# LPC54S018M register map
Vendor: nxp.com; File version: 1.0
CPU: CM4 r0p1, little endian, MPU, FPU, VTOR, 3 interrupt priority bits
Registers are 32-bit, read-write, reset 0x0 unless marked. A register's access mark holds for its fields unless they carry their own. Offsets are from the block's base; [hi:lo] are bit positions; {n}, {i} and the like mark numbered series; 'fields as' and 'values as' point back to an identical list.

## CRC_ENGINE — LPC5411x CRC engine
Base 0x40095000
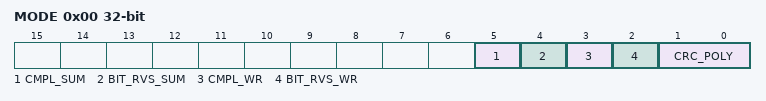
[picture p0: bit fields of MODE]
0x00 MODE — CRC mode register
  [5] CMPL_SUM — CRC sum complement: 1 = 1's complement for CRC_SUM 0 = No 1's complement for CRC_SUM
  [4] BIT_RVS_SUM — CRC sum bit order: 1 = Bit order reverse for CRC_SUM 0 = No bit order reverse for CRC_SUM
  [3] CMPL_WR — Data complement: 1 = 1's complement for CRC_WR_DATA 0 = No 1's complement for CRC_WR_DATA
  [2] BIT_RVS_WR — Data bit order: 1 = Bit order reverse for CRC_WR_DATA (per byte) 0 = No bit order reverse for CRC_WR_DATA (per byte)
  [1:0] CRC_POLY — CRC polynomial: 1X = CRC-32 polynomial 01 = CRC-16 polynomial 00 = CRC-CCITT polynomial
0x04 SEED reset 0xFFFF — CRC seed register
  [31:0] CRC_SEED — A write access to this register will load CRC seed value to CRC_SUM register with selected bit order and 1's complement pre-processes. A write access to this register will overrule the CRC calculation in progresses.
0x08 SUM ro reset 0xFFFF (SUM_WR_DATA view) — CRC checksum register
  [31:0] CRC_SUM — The most recent CRC sum can be read through this register with selected bit order and 1's complement post-processes.
0x08 WR_DATA wo (SUM_WR_DATA view) — CRC data register
  [31:0] CRC_WR_DATA — Data written to this register will be taken to perform CRC calculation with selected bit order and 1's complement pre-process. Any write size 8, 16 or 32-bit are allowed and accept back-to-back transactions.

## AES0 — AES
Base 0x400A1000
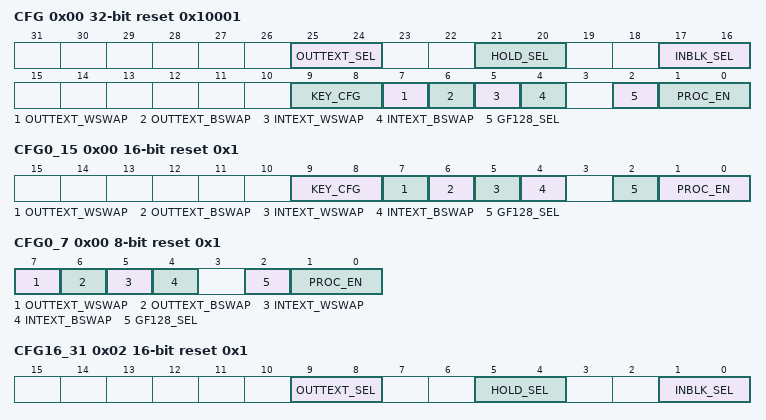
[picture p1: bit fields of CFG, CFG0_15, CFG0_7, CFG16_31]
0x00 CFG reset 0x10001 (CFG_CFG0_15_CFG0_7 view) — AES Configuration register
  [25:24] OUTTEXT_SEL — Output text source select.
  [21:20] HOLD_SEL — Holding register source select.
  [17:16] INBLK_SEL — Input block select.
  [9:8] KEY_CFG — Key Configuration.
  [7] OUTTEXT_WSWAP — Word swap output text.
  [6] OUTTEXT_BSWAP — Byte swap output text.
  [5] INTEXT_WSWAP — Word swap input text.
  [4] INTEXT_BSWAP — Byte swap input text.
  [2] GF128_SEL — GF128 hash selection.
  [1:0] PROC_EN — Process type enable.
0x00 CFG0_15 16-bit reset 0x1 (CFG_CFG0_15_CFG0_7 view) — AES Configuration register 0:15
  [9:8] KEY_CFG — Key Configuration.
  [7] OUTTEXT_WSWAP — Word swap output text.
  [6] OUTTEXT_BSWAP — Byte swap output text.
  [5] INTEXT_WSWAP — Word swap input text.
  [4] INTEXT_BSWAP — Byte swap input text.
  [2] GF128_SEL — GF128 hash selection.
  [1:0] PROC_EN — Process type enable.
0x00 CFG0_7 8-bit reset 0x1 (CFG_CFG0_15_CFG0_7 view) — AES Configuration register 0:7
  [7] OUTTEXT_WSWAP — Word swap output text.
  [6] OUTTEXT_BSWAP — Byte swap output text.
  [5] INTEXT_WSWAP — Word swap input text.
  [4] INTEXT_BSWAP — Byte swap input text.
  [2] GF128_SEL — GF128 hash selection.
  [1:0] PROC_EN — Process type enable.
0x01 CFG8_15 8-bit — AES Configuration register 8:15
  [1:0] KEY_CFG — Key Configuration.
0x02 CFG16_31 16-bit reset 0x1 — AES Configuration register 16:31
  [9:8] OUTTEXT_SEL — Output text source select.
  [5:4] HOLD_SEL — Holding register source select.
  [1:0] INBLK_SEL — Input block select.
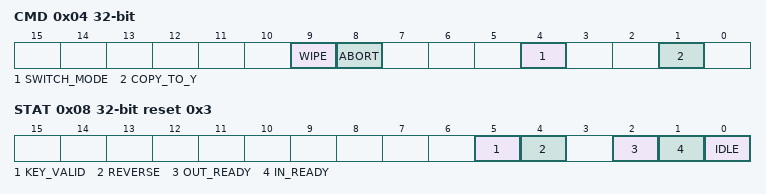
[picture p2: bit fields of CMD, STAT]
0x04 CMD — AES Command register
  [9] WIPE — When set this bit performs abort, clears KEY and GF128_Y registers and disables cipher.
  [8] ABORT — Aborts Encrypt/Decrypt and GF128 Hash operation.
  [4] SWITCH_MODE — When this bit is set the mode switches from forward mode (encryption) to reverse mode (decryption) or reverse mode to forward mode.
  [1] COPY_TO_Y — Copy output text to GF128Y.
0x08 STAT reset 0x3 — AES Status register
  [5] KEY_VALID
  [4] REVERSE — Reverse mode.
  [2] OUT_READY — Output text ready.
  [1] IN_READY — Input text ready.
  [0] IDLE — AES engine Idle.
0x0C CTR_INCR — Counter Increment
  [31:0] CTR_INCR — Increment value for HOLDING register when in counter modes.
{0x20+4i} KEY[{i}] (i=0..7) wo — Bits of the AES key
  [31:0] KEY — Contains the bits of the AES key.
{0x40+4i} INTEXT[{i}] (i=0..3) wo — Input text bits
  [31:0] INTEXT — Contains bits of the AES key.
{0x50+4i} HOLDING[{i}] (i=0..3) wo — Holding register bits
  [31:0] HOLDING — Contains the first word (bits 31:0) of the 128 bit Holding value.
{0x60+4i} OUTTEXT[{i}] (i=0..3) ro — Output text bits
  [31:0] OUTTEXT — Contains the bits of the 128 bit Output text data.
{0x70+4i} GF128_Y[{i}] (i=0..3) wo — Y bits input of GF128 hash
  [31:0] GF128_Y — Contains the bits of the Y input of GF128 hash.
{0x80+4i} GF128_Z[{i}] (i=0..3) ro — Result bits of GF128 hash
  [31:0] GF128_Z — Contains bits of the result of GF128 hash.
{0x90+4i} GCM_TAG[{i}] (i=0..3) ro — GCM Tag bits
  [31:0] GCM_TAG — Contains bits of the 128 bit GCM tag.

## SHA0 — SHA
Base 0x400A4000
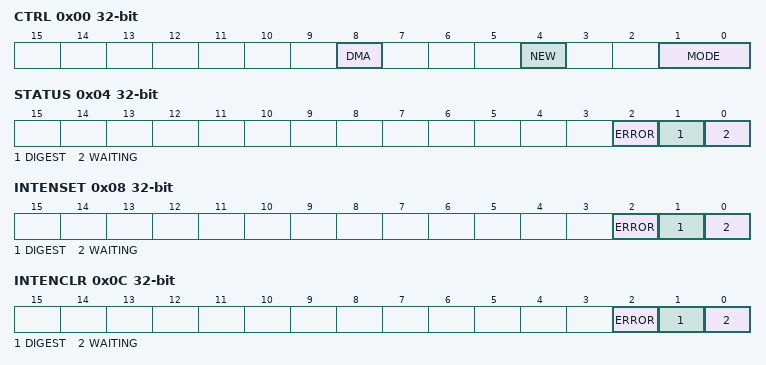
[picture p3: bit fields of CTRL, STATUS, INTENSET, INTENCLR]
0x00 CTRL — Control register
  [8] DMA — When this bit is set, the DMA is used to fill INDATA.
  [4] NEW — When this bit is set, a new hash operation is started.
  [1:0] MODE — This field is used to select the operational mode of SHA block.
0x04 STATUS
  [2] ERROR — This field indicates if an error has occurred.
  [1] DIGEST — This field indicates if a DIGEST is ready and waiting and there is no active next block that has already started.
  [0] WAITING — This field indicates if the block is waiting for more data to process.
0x08 INTENSET — Interrupt Enable register
  [2] ERROR — This field indicates if interrupt is generated on an ERROR (as defined in STAT register).
  [1] DIGEST — This field indicates if interrupt is generated when Digest is ready (completed a Hash or completed a full sequence).
  [0] WAITING — This field indicates if interrupt should be enabled when waiting for input data.
0x0C INTENCLR wo — Interrupt Clear register
  [2] ERROR — Writing a 1 clears the interrupt enabled by the INTENSET register.
  [1] DIGEST — Writing a 1 clears the interrupt enabled by the INTENSET register.
  [0] WAITING — Writing a 1 clears the interrupt enabled by the INTENSET register.
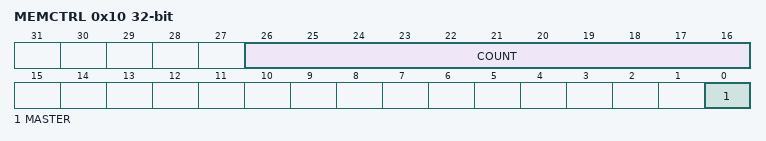
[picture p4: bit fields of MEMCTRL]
0x10 MEMCTRL — Memory Control register
  [26:16] COUNT — This field indicates the number of 512-bit blocks to copy starting at MEMADDR.
  [0] MASTER — This field is used to enable SHA block as AHB bus master.
0x14 MEMADDR — Memory Address register
  [31:0] BASEADDR — This field indicates the base address in Internal Flash, SRAM0, SRAMX, or SPIFI to start copying from.
0x20 INDATA wo — Input Data register
  [31:0] DATA — In this field the next word is written in little-endian format.
{0x24+4i} ALIAS[{i}] (i=0..6) wo
  fields as INDATA
{0x40+4i} DIGEST[{i}] (i=0..7) ro
  [31:0] DIGEST — This field contains one word of the Digest.
